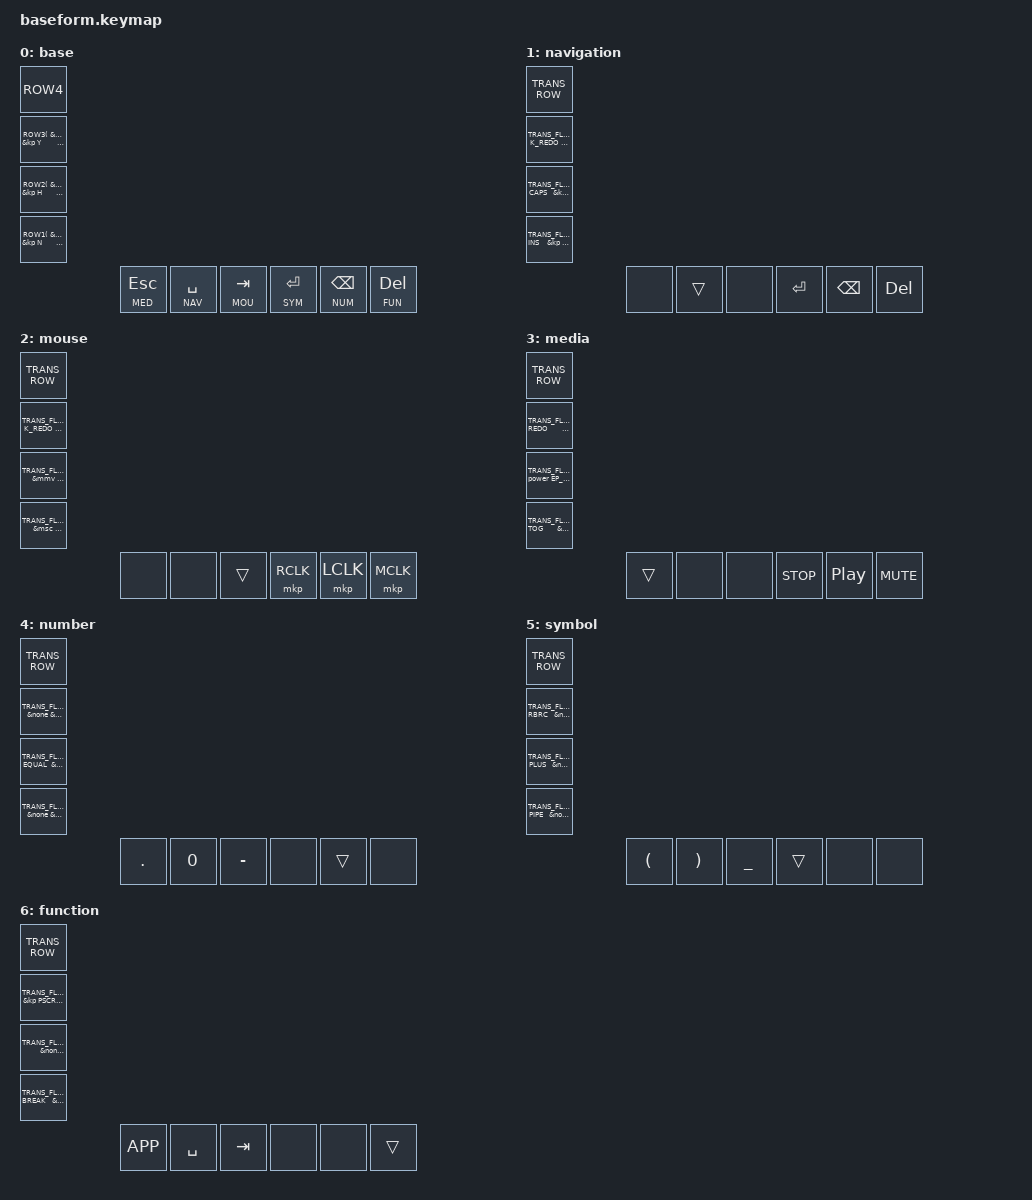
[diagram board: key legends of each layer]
#include <behaviors.dtsi>
#include <dt-bindings/zmk/keys.h>
#include <dt-bindings/zmk/bt.h>
#include <dt-bindings/zmk/ext_power.h>
#include <dt-bindings/zmk/outputs.h>
#include <dt-bindings/zmk/pointing.h>
#include "../keymap_edges.dtsi"

// Mouse movement settings
#define ZMK_POINTING_DEFAULT_MOVE_VAL 3000
#define ZMK_MOUSE_DEFAULT_MOVE_VAL 3000

#define QWE 0
#define NAV 1
#define MOU 2
#define MED 3
#define NUM 4
#define SYM 5
#define FUN 6

&lt {
  tapping-term-ms = <150>;
  quick_tap_ms = <150>;
};

&soft_off {
    hold-time-ms = <2000>; 
};

/ {

  behaviors {
    hm: htt {
      compatible = "zmk,behavior-hold-tap";
      label = "HOLD_TAP_TUNED";
      #binding-cells = <2>;
      tapping-term-ms = <170>;
      quick_tap_ms = <170>;
      flavor = "tap-preferred";
      bindings = <&kp>, <&kp>;
    };
  };

  keymap {
    compatible = "zmk,keymap";

    base_layer {
      display-name = "base";
      bindings = <
        ROW4
        ROW3( &kp Q       &kp W       &kp E        &kp R         &kp T          &kp Y         &kp U          &kp I         &kp O         &kp P          )
        ROW2( &hm LGUI A  &hm LALT S  &hm LCTRL D  &hm LSHFT F   &kp G          &kp H         &hm RSHIFT J   &hm RCTRL K   &hm  RALT L   &hm RGUI APOS  )
        ROW1( &kp Z       &kp X       &kp C        &kp V         &kp B          &kp N         &kp M          &kp COMMA     &kp DOT       &kp SLASH      )
                                      &lt MED ESC   &lt NAV SPACE &lt MOU TAB    &lt SYM ENTER &lt NUM BSPC   &lt FUN DEL
      >;
    };
  
  navigation_layer {
    display-name = "navigation";
    bindings = <
      TRANS_ROW
      TRANS_FLANK( &none    &none    &none     &none     &none     &kp K_REDO &kp K_PASTE    &kp K_COPY     &kp K_CUT    &kp K_UNDO )
      TRANS_FLANK( &kp LGUI &kp LALT &kp LCTRL &kp LSHFT &none     &kp CAPS   &kp LEFT_ARROW &kp DOWN_ARROW &kp UP_ARROW &kp RIGHT_ARROW  )
      TRANS_FLANK( &none    &none    &none     &none     &none     &kp INS    &kp HOME    &kp PG_DN         &kp PG_UP    &kp END    )
                                     &none     &trans    &none     &kp ENTER  &kp BSPC    &kp DEL
    >;
  };

  mouse_layer {
    display-name = "mouse";
    bindings = <
      TRANS_ROW
      TRANS_FLANK( &none    &none    &none     &none     &none     &kp K_REDO &kp K_PASTE    &kp K_COPY     &kp K_CUT    &kp K_UNDO )
      TRANS_FLANK( &kp LGUI &kp LALT &kp LCTRL &kp LSHFT &none     &none      &mmv MOVE_LEFT &mmv MOVE_DOWN &mmv MOVE_UP &mmv MOVE_RIGHT )
      TRANS_FLANK( &none    &none    &none     &none     &none     &none      &msc SCRL_LEFT &msc SCRL_DOWN &msc SCRL_UP &msc SCRL_RIGHT )
                                     &none    &none     &trans     &mkp RCLK  &mkp LCLK      &mkp MCLK
    >;
  };

  media_layer {
    display-name = "media";
    bindings = <
      TRANS_ROW
      TRANS_FLANK( &none    &none    &none     &none     &none     &kp K_REDO         &kp K_PASTE  &kp K_COPY     &kp K_CUT     &kp K_UNDO   )
      TRANS_FLANK( &kp LGUI &kp LALT &kp LCTRL &kp LSHFT &none     &ext_power EP_TOG  &kp C_PREV   &kp C_VOL_DN   &kp C_VOL_UP  &kp C_NEXT   )
      TRANS_FLANK( &none    &none    &none     &none     &none     &out OUT_TOG       &bt BT_SEL 0 &bt BT_SEL 1   &bt BT_SEL 2  &bt BT_SEL 3 )
                                     &trans    &none     &none     &kp C_STOP         &kp C_PP     &kp C_MUTE
    >;
  };

  number_layer {
    display-name = "number";
    bindings = <
      TRANS_ROW
      TRANS_FLANK( &kp LBKT  &kp N7 &kp N8  &kp N9 &kp RBKT   &none &none      &none     &none    &none    )
      TRANS_FLANK( &kp SEMI  &kp N4 &kp N5  &kp N6 &kp EQUAL  &none &kp RSHIFT &kp RCTRL &kp RALT &kp RGUI )
      TRANS_FLANK( &kp GRAVE &kp N1 &kp N2  &kp N3 &kp BSLH   &none &none      &none     &none    &none    )
                                    &kp DOT &kp N0 &kp MINUS  &none &trans     &none
    >;
  };

  symbol_layer {
    display-name = "symbol";
    bindings = <
      TRANS_ROW
      TRANS_FLANK( &kp LBRC  &kp AMPS &kp STAR  &kp LPAR  &kp RBRC   &none  &none      &none     &none    &none    )
      TRANS_FLANK( &kp COLON &kp DLLR &kp PRCNT &kp CARET &kp PLUS   &none  &kp RSHIFT &kp RCTRL &kp RALT &kp RGUI )
      TRANS_FLANK( &kp TILDE &kp EXCL &kp AT    &kp HASH  &kp PIPE   &none  &none      &none     &none    &none    )
                                      &kp LPAR  &kp RPAR  &kp UNDER  &trans &none &none 
    >;
  };

  function_layer {
    display-name = "function";
    bindings = <
      TRANS_ROW
      TRANS_FLANK( &kp F12 &kp F7 &kp F8    &kp F9    &kp PSCRN         &none &none &none &none &none )
      TRANS_FLANK( &kp F11 &kp F4 &kp F5    &kp F6    &kp SLCK          &none  &kp RSHIFT &kp RCTRL &kp RALT &kp RGUI )
      TRANS_FLANK( &kp F10 &kp F1 &kp F2    &kp F3    &kp PAUSE_BREAK   &none  &none      &none     &none    &none    )
                                  &kp K_APP &kp SPACE &kp TAB           &none  &none      &trans
    >;
  };

  };
};
